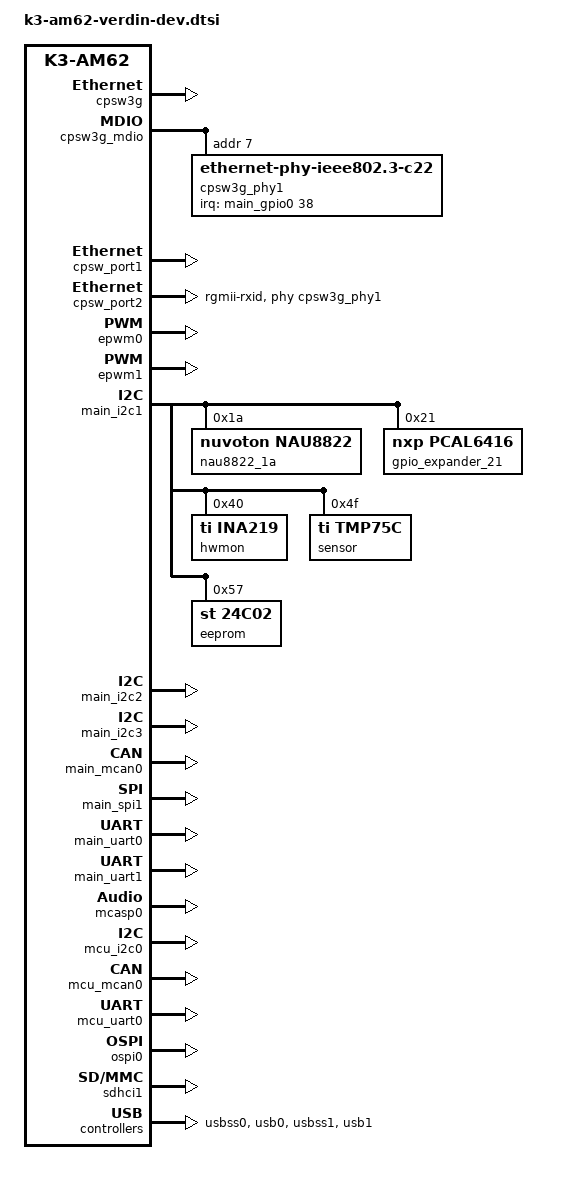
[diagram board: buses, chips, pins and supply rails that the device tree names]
/ {
	sound {
		compatible = "simple-audio-card";
		simple-audio-card,bitclock-master = <&codec_dai>;
		simple-audio-card,format = "i2s";
		simple-audio-card,frame-master = <&codec_dai>;
		simple-audio-card,name = "verdin-nau8822";
		simple-audio-card,routing =
			"Headphones", "LHP",
			"Headphones", "RHP",
			"Speaker", "LSPK",
			"Speaker", "RSPK",
			"Line Out", "AUXOUT1",
			"Line Out", "AUXOUT2",
			"LAUX", "Line In",
			"RAUX", "Line In",
			"LMICP", "Mic In",
			"RMICP", "Mic In";
		simple-audio-card,widgets =
			"Headphones", "Headphones",
			"Line Out", "Line Out",
			"Speaker", "Speaker",
			"Microphone", "Mic In",
			"Line", "Line In";
		codec_dai: simple-audio-card,codec {
			clocks = <&audio_refclk1>;
			sound-dai = <&nau8822_1a>;
		};
		simple-audio-card,cpu {
			sound-dai = <&mcasp0>;
		};
	};
};
&cpsw3g {
	pinctrl-names = "default";
	pinctrl-0 = <&pinctrl_rgmii1>, <&pinctrl_rgmii2>;
	status = "okay";
};
&cpsw3g_mdio {
	status = "okay";
	cpsw3g_phy1: ethernet-phy@7 {
		compatible = "ethernet-phy-ieee802.3-c22";
		reg = <7>;
		interrupt-parent = <&main_gpio0>;
		interrupts = <38 IRQ_TYPE_EDGE_FALLING>;
		pinctrl-names = "default";
		pinctrl-0 = <&pinctrl_eth2_rgmii_int>;
		micrel,led-mode = <0>;
	};
};
&cpsw_port1 {
	status = "okay";
};
&cpsw_port2 {
	phy-handle = <&cpsw3g_phy1>;
	phy-mode = "rgmii-rxid";
	status = "okay";
};
&epwm0 {
	status = "okay";
};
&epwm1 {
	status = "okay";
};
&main_gpio0 {
	pinctrl-names = "default";
	pinctrl-0 = <&pinctrl_ctrl_sleep_moci>,
		    <&pinctrl_gpio_5>,
		    <&pinctrl_gpio_6>,
		    <&pinctrl_gpio_7>,
		    <&pinctrl_gpio_8>;
};
&main_i2c1 {
	status = "okay";
	nau8822_1a: audio-codec@1a {
		compatible = "nuvoton,nau8822";
		reg = <0x1a>;
		pinctrl-names = "default";
		pinctrl-0 = <&pinctrl_i2s1_mclk>;
		#sound-dai-cells = <0>;
	};
	gpio_expander_21: gpio@21 {
		compatible = "nxp,pcal6416";
		reg = <0x21>;
		#gpio-cells = <2>;
		gpio-controller;
	};
	hwmon@40 {
		compatible = "ti,ina219";
		reg = <0x40>;
		shunt-resistor = <10000>;
	};
	sensor@4f {
		compatible = "ti,tmp75c";
		reg = <0x4f>;
	};
	eeprom@57 {
		compatible = "st,24c02", "atmel,24c02";
		reg = <0x57>;
		pagesize = <16>;
	};
};
&main_i2c2 {
	status = "okay";
};
&main_i2c3 {
	status = "okay";
};
&main_mcan0 {
	status = "okay";
};
&main_spi1 {
	status = "okay";
};
&main_uart0 {
	status = "okay";
};
&main_uart1 {
	linux,rs485-enabled-at-boot-time;
	rs485-rx-during-tx;
	status = "okay";
};
&mcasp0 {
	status = "okay";
};
&mcu_gpio0 {
	pinctrl-names = "default";
	pinctrl-0 = <&pinctrl_gpio_1>,
		    <&pinctrl_gpio_2>,
		    <&pinctrl_gpio_3>,
		    <&pinctrl_gpio_4>;
};
&mcu_i2c0 {
	status = "okay";
};
&mcu_mcan0 {
	status = "okay";
};
&mcu_uart0 {
	status = "okay";
};
&ospi0 {
	status = "okay";
};
&sdhci1 {
	ti,driver-strength-ohm = <33>;
	status = "okay";
};
&usbss0 {
	status = "okay";
};
&usb0 {
	status = "okay";
};
&usbss1 {
	status = "okay";
};
&usb1 {
	status = "okay";
};
&verdin_gpio_keys {
	status = "okay";
};
&wkup_uart0 {
	status = "reserved";
};
